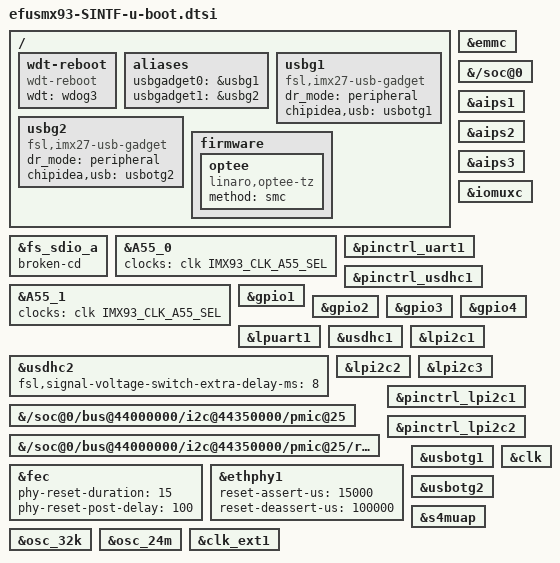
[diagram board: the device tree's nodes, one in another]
// SPDX-License-Identifier: GPL-2.0
/*
* Copyright 2024 F&S Elektronik Systeme GmbH
*
* This program is free software; you can redistribute it and/or modify
* it under the terms of the GNU General Public License version 2 as
* published by the Free Software Foundation.
*
* This program is distributed in the hope that it will be useful,
* but WITHOUT ANY WARRANTY; without even the implied warranty of
* MERCHANTABILITY or FITNESS FOR A PARTICULAR PURPOSE.  See the
* GNU General Public License for more details.
*/

/ {
	wdt-reboot {
		compatible = "wdt-reboot";
		wdt = <&wdog3>;
		bootph-pre-ram;
		bootph-some-ram;
	};

	aliases {
		usbgadget0 = &usbg1;
		usbgadget1 = &usbg2;
	};

	usbg1: usbg1 {
		compatible = "fsl,imx27-usb-gadget";
		dr_mode = "peripheral";
		chipidea,usb = <&usbotg1>;
		status = "okay";
	};

	usbg2: usbg2 {
		compatible = "fsl,imx27-usb-gadget";
		dr_mode = "peripheral";
		chipidea,usb = <&usbotg2>;
		status = "okay";
	};

	firmware {
		optee {
			compatible = "linaro,optee-tz";
			method = "smc";
		};
	};
};

&emmc {
	/delete-property/ vmmc-supply;
	/delete-property/ vqmmc-supply;
};

&fs_sdio_a {
	/delete-property/ vmmc-supply;
	/*
	* TODO:
	* There seems to be an issue with card detection (CD) in U-Boot.
	* This requires further investigation.
	* The `broken-cd` property is set, which has the same effect as "non-removable".
	* As a result, `sdhci_get_cd()` will always return true, which is acceptable for U-Boot.
	* It is still possible to switch SD cards on this port.
	* Reinitialization using `mmc dev <x>` might be required!
	*/
	broken-cd;
};


&{/soc@0} {
	bootph-all;
	bootph-pre-ram;
};

&A55_0 {
	clocks = <&clk IMX93_CLK_A55_SEL>;
};

&A55_1 {
	clocks = <&clk IMX93_CLK_A55_SEL>;
};

&aips1 {
	bootph-all;
	bootph-pre-ram;
};

&aips2 {
	bootph-pre-ram;
	bootph-some-ram;
};

&aips3 {
	bootph-pre-ram;
	bootph-some-ram;
};

&iomuxc {
	bootph-pre-ram;
	bootph-some-ram;
};

&pinctrl_uart1 {
	bootph-pre-ram;
	bootph-some-ram;
};

&pinctrl_usdhc1 {
	bootph-pre-ram;
};

&gpio1 {
	bootph-pre-ram;
	bootph-some-ram;

	/* not used in U-Boot, save memory in SPL*/
	/delete-property/ gpio-line-names;
};

&gpio2 {
	bootph-pre-ram;
	bootph-some-ram;

	/* not used in U-Boot, save memory in SPL*/
	/delete-property/ gpio-line-names;
};

&gpio3 {
	bootph-pre-ram;
	bootph-some-ram;

	/* not used in U-Boot, save memory in SPL*/
	/delete-property/ gpio-line-names;
};

&gpio4 {
	bootph-pre-ram;
	bootph-some-ram;

	/* not used in U-Boot, save memory in SPL*/
	/delete-property/ gpio-line-names;
};

&lpuart1 {
	bootph-pre-ram;
	bootph-some-ram;
};

&usdhc1 {
	bootph-pre-ram;
};

&usdhc2 {
	fsl,signal-voltage-switch-extra-delay-ms = <8>;
};

&lpi2c1 {
	bootph-pre-ram;
};

&lpi2c2 {
	bootph-pre-ram;
};

&lpi2c3 {
	bootph-pre-ram;
};

&{/soc@0/bus@44000000/i2c@44350000/pmic@25} {
	bootph-pre-ram;
};

&{/soc@0/bus@44000000/i2c@44350000/pmic@25/regulators} {
	bootph-pre-ram;
};

&pinctrl_lpi2c1 {
	bootph-pre-ram;
};

&pinctrl_lpi2c2 {
	bootph-pre-ram;
};

&fec {
	phy-reset-duration = <15>;
	phy-reset-post-delay = <100>;
};

&ethphy1 {
	reset-assert-us = <15000>;
	reset-deassert-us = <100000>;
};

&usbotg1 {
	status = "okay";
};

&usbotg2 {
	status = "okay";
};

&s4muap {
	bootph-pre-ram;
	bootph-some-ram;
	status = "okay";
};

&clk {
	bootph-all;
	bootph-pre-ram;
	/delete-property/ assigned-clocks;
	/delete-property/ assigned-clock-rates;
	/delete-property/ assigned-clock-parents;
};

&osc_32k {
	bootph-all;
	bootph-pre-ram;
};

&osc_24m {
	bootph-all;
	bootph-pre-ram;
};

&clk_ext1 {
	bootph-all;
	bootph-pre-ram;
};
